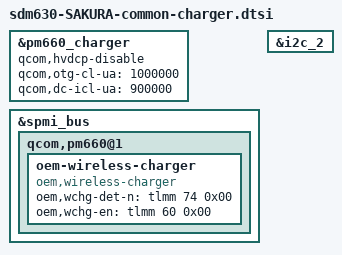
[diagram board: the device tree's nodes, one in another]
/*
 * This software is contributed or developed by KYOCERA Corporation.
 * (C) 2018 KYOCERA Corporation
 *
 * This program is free software; you can redistribute it and/or modify
 * it under the terms of the GNU General Public License version 2 and
 * only version 2 as published by the Free Software Foundation.
 *
 * This program is distributed in the hope that it will be useful,
 * but WITHOUT ANY WARRANTY; without even the implied warranty of
 * MERCHANTABILITY or FITNESS FOR A PARTICULAR PURPOSE.  See the
 * GNU General Public License for more details.
 */

&pm660_charger {
	qcom,hvdcp-disable;
	qcom,otg-cl-ua = <1000000>;
	qcom,dc-icl-ua = <900000>;
};

&spmi_bus {
	qcom,pm660@1 {
		oem-wireless-charger {
			compatible = "oem,wireless-charger";
			oem,wchg-det-n = <&tlmm 74 0x00>;
			oem,wchg-en = <&tlmm 60 0x00>;
		};
	};
};

&i2c_2 {
	/delete-node/ smb1351-charger@1d;
};
